AUTOSAR XML (schema 4-3-0)
standard types defined: boolean, uint32, uint8, boolean_CompuMethod, boolean_DataConstr, uint32_DataConstr, uint8_DataConstr
package /ComponentTypes/HkmcDiagSWC
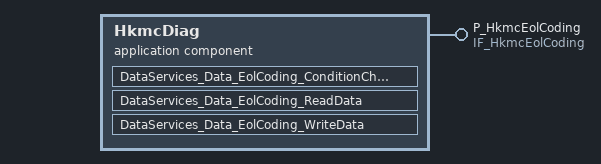
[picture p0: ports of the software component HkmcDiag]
  application sw component type HkmcDiag
    provide port P_HkmcEolCoding: provided-interface=IF_HkmcEolCoding
      provided-com-specs:
        operation=DataServices_Data_EolCoding_ConditionCheckRead, queue-length=1
        operation=DataServices_Data_EolCoding_ReadData, queue-length=1
        operation=DataServices_Data_EolCoding_WriteData, queue-length=1
    behavior HkmcDiag_InternalBehavior
      operation invoked event OIT_DataServices_Data_EolCoding_ConditionCheckRead_P_HkmcEolCoding_DataServices_Data_EolCoding_ConditionCheckRead: start-on-event=DataServices_Data_EolCoding_ConditionCheckRead, operation=P_HkmcEolCoding.DataServices_Data_EolCoding_ConditionCheckRead
      operation invoked event OIT_DataServices_Data_EolCoding_ReadData_P_HkmcEolCoding_DataServices_Data_EolCoding_ReadData: start-on-event=DataServices_Data_EolCoding_ReadData, operation=P_HkmcEolCoding.DataServices_Data_EolCoding_ReadData
      operation invoked event OIT_DataServices_Data_EolCoding_WriteData_P_HkmcEolCoding_DataServices_Data_EolCoding_WriteData: start-on-event=DataServices_Data_EolCoding_WriteData, operation=P_HkmcEolCoding.DataServices_Data_EolCoding_WriteData
      runnable DataServices_Data_EolCoding_ConditionCheckRead
      runnable DataServices_Data_EolCoding_ReadData
      runnable DataServices_Data_EolCoding_WriteData
  swc implementation HkmcDiag_Implementation: behavior=HkmcDiag_InternalBehavior
    code-descriptors:
      code Default: artifact-descriptors=autosar-engineering-object={short-label=Default, category=SWSRC}
package /ComponentTypes/HkmcDiagSWC/PortInterfaces
  client server interface IF_HkmcEolCoding: is-service=true
    operation DataServices_Data_EolCoding_ConditionCheckRead
      arg DcmOpStatusIn: type=Dcm_OpStatusType, direction=IN, server-argument-impl-policy=USE-ARGUMENT-TYPE
      arg DcmNegativeResponseCodeOut: type=Dcm_NegativeResponseCodeType, direction=OUT, server-argument-impl-policy=USE-ARGUMENT-TYPE
    operation DataServices_Data_EolCoding_ReadData
      arg DcmOpStatusIn: type=Dcm_OpStatusType, direction=IN, server-argument-impl-policy=USE-ARGUMENT-TYPE
      arg ReadStatus: type=boolean, direction=OUT, server-argument-impl-policy=USE-ARGUMENT-TYPE
      arg DCMbufferIn: type=uint32, direction=IN, server-argument-impl-policy=USE-ARGUMENT-TYPE
    operation DataServices_Data_EolCoding_WriteData
      arg DcmOpStatusIn: type=Dcm_OpStatusType, direction=IN, server-argument-impl-policy=USE-ARGUMENT-TYPE
      arg WriteStatus: type=boolean, direction=OUT, server-argument-impl-policy=USE-ARGUMENT-TYPE
      arg DCMbufferIn: type=uint32, direction=IN, server-argument-impl-policy=USE-ARGUMENT-TYPE
    error DCM_E_PENDING: error-code=10
    error E_NOT_OK: error-code=1
package /MICROSAR/Dcm_swc/DataTypes
  impl type Dcm_NegativeResponseCodeType:
    compu {0=DCM_E_POSITIVERESPONSE, 16=DCM_E_GENERALREJECT, 17=DCM_E_SERVICENOTSUPPORTED, 18=DCM_E_SUBFUNCTIONNOTSUPPORTED, 19=DCM_E_INCORRECTMESSAGELENGTHORINVALIDFORMAT, 20=DCM_E_RESPONSETOOLONG, 33=DCM_E_BUSYREPEATREQUEST, 34=DCM_E_CONDITIONSNOTCORRECT, 36=DCM_E_REQUESTSEQUENCEERROR, 37=DCM_E_NORESPONSEFROMSUBNETCOMPONENT, 38=DCM_E_FAILUREPREVENTSEXECUTIONOFREQUESTEDACTION, 49=DCM_E_REQUESTOUTOFRANGE, 51=DCM_E_SECURITYACCESSDENIED, 53=DCM_E_INVALIDKEY, 54=DCM_E_EXCEEDNUMBEROFATTEMPTS, 55=DCM_E_REQUIREDTIMEDELAYNOTEXPIRED, 112=DCM_E_UPLOADDOWNLOADNOTACCEPTED, 113=DCM_E_TRANSFERDATASUSPENDED, 114=DCM_E_GENERALPROGRAMMINGFAILURE, 115=DCM_E_WRONGBLOCKSEQUENCECOUNTER, 120=DCM_E_REQUESTCORRECTLYRECEIVEDRESPONSEPENDING, 126=DCM_E_SUBFUNCTIONNOTSUPPORTEDINACTIVESESSION, 127=DCM_E_SERVICENOTSUPPORTEDINACTIVESESSION, 129=DCM_E_RPMTOOHIGH, 130=DCM_E_RPMTOOLOW, 131=DCM_E_ENGINEISRUNNING, 132=DCM_E_ENGINEISNOTRUNNING, 133=DCM_E_ENGINERUNTIMETOOLOW, 134=DCM_E_TEMPERATURETOOHIGH, 135=DCM_E_TEMPERATURETOOLOW, 136=DCM_E_VEHICLESPEEDTOOHIGH, 137=DCM_E_VEHICLESPEEDTOOLOW, 138=DCM_E_THROTTLE_PEDALTOOHIGH, 139=DCM_E_THROTTLE_PEDALTOOLOW, 140=DCM_E_TRANSMISSIONRANGENOTINNEUTRAL, 141=DCM_E_TRANSMISSIONRANGENOTINGEAR, 143=DCM_E_BRAKESWITCH_NOTCLOSED, 144=DCM_E_SHIFTERLEVERNOTINPARK, 145=DCM_E_TORQUECONVERTERCLUTCHLOCKED, 146=DCM_E_VOLTAGETOOHIGH, 147=DCM_E_VOLTAGETOOLOW, 240..249=DCM_E_VMSCNC_0..DCM_E_VMSCNC_9, 250=DCM_E_VMSCNC_A, 251=DCM_E_VMSCNC_B, 252=DCM_E_VMSCNC_C, 253=DCM_E_VMSCNC_D, 254=DCM_E_VMSCNC_E}
    range raw 0..254
    implementation-data-type=uint8
  impl type Dcm_OpStatusType: compu {0=DCM_INITIAL, 1=DCM_PENDING, 2=DCM_CANCEL, 3=DCM_FORCE_RCRRP_OK, 64=DCM_FORCE_RCRRP_NOT_OK}, range raw 0..64, implementation-data-type=uint8
